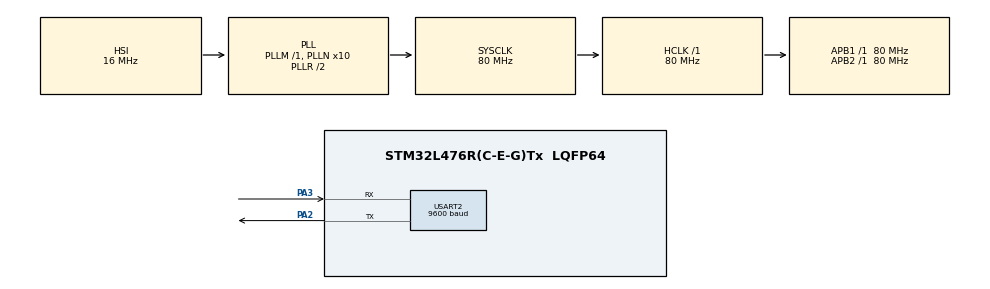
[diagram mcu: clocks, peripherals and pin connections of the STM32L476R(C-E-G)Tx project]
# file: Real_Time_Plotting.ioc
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Mcu.Family=STM32L4
Mcu.Name=STM32L476R(C-E-G)Tx
Mcu.Package=LQFP64
NVIC.PriorityGroup=NVIC_PRIORITYGROUP_4
NVIC.USART2_IRQn=true\:0\:0\:false\:false\:true\:true\:true\:true
PA2.Mode=Asynchronous
PA2.Signal=USART2_TX
PA3.Mode=Asynchronous
PA3.Signal=USART2_RX
ProjectManager.HeapSize=0x200
ProjectManager.StackSize=0x400
ProjectManager.TargetToolchain=STM32CubeIDE
RCC.ADCFreq_Value=64000000
RCC.AHBFreq_Value=80000000
RCC.APB1Freq_Value=80000000
RCC.APB1TimFreq_Value=80000000
RCC.APB2Freq_Value=80000000
RCC.APB2TimFreq_Value=80000000
RCC.CortexFreq_Value=80000000
RCC.HCLKFreq_Value=80000000
RCC.HSE_VALUE=8000000
RCC.HSI_VALUE=16000000
RCC.LSE_VALUE=32768
RCC.MSI_VALUE=4000000
RCC.PLLN=10
RCC.PLLSourceVirtual=RCC_PLLSOURCE_HSI
RCC.PREFETCH_ENABLE=1
RCC.SYSCLKFreq_VALUE=80000000
RCC.SYSCLKSource=RCC_SYSCLKSOURCE_PLLCLK
RCC.USBFreq_Value=64000000
RCC.VCOOutputFreq_Value=160000000
USART2.BaudRate=9600
USART2.VirtualMode-Asynchronous=VM_ASYNC
board=NUCLEO-L476RG

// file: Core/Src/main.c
/* USER CODE BEGIN Header */
/**
  ******************************************************************************
  * @file           : main.c
  * @brief          : Main program body
  ******************************************************************************
  * @attention
  *
  * Copyright (c) 2023 STMicroelectronics.
  * All rights reserved.
  *
  * This software is licensed under terms that can be found in the LICENSE file
  * in the root directory of this software component.
  * If no LICENSE file comes with this software, it is provided AS-IS.
  *
  ******************************************************************************
  */
/* USER CODE END Header */
#include "main.h"

/* USER CODE BEGIN Includes */
#include "stdlib.h"
#include "stdio.h"
#include "string.h"
#include "stdbool.h"

/* USER CODE END Includes */

UART_HandleTypeDef huart2;

/* USER CODE BEGIN PV */

char Tx_Buffer[50];
uint8_t Rx_Buffer[1];

/* USER CODE END PV */

void SystemClock_Config(void);
static void MX_GPIO_Init(void);
static void MX_USART2_UART_Init(void);

int main(void)
{

  /* MCU Configuration--------------------------------------------------------*/

  /* Reset of all peripherals, Initializes the Flash interface and the Systick. */
  HAL_Init();

  /* Configure the system clock */
  SystemClock_Config();

  /* Initialize all configured peripherals */
  MX_GPIO_Init();
  MX_USART2_UART_Init();

  /* USER CODE BEGIN 2 */

  bool data_stream_active = false;

  // Read data from the PC (Python code request).
  while (1) {
      HAL_UART_Receive(&huart2, (uint8_t *)Rx_Buffer, sizeof(Rx_Buffer), 100);
      // Check the request
      if (Rx_Buffer[0] == 103) { // if the user enters the 'g' character
          if (!data_stream_active) {
              //sprintf(Tx_Buffer, "Data stream initiated\n"); python script will handle logging infos to the user.
              HAL_UART_Transmit(&huart2, (uint8_t *)Tx_Buffer, strlen(Tx_Buffer), 100);
              data_stream_active = true;
          } else {
              //sprintf(Tx_Buffer, "Data stream already active\n");
              HAL_UART_Transmit(&huart2, (uint8_t *)Tx_Buffer, strlen(Tx_Buffer), 100);
          }
      } else if (Rx_Buffer[0] == 115) { // if the user enters the 's' character
          if (data_stream_active) {
              //sprintf(Tx_Buffer, "Data stream stopped\n");
              HAL_UART_Transmit(&huart2, (uint8_t *)Tx_Buffer, strlen(Tx_Buffer), 100);
              data_stream_active = false;
          } else {
              sprintf(Tx_Buffer, "Data stream not active\n");
              HAL_UART_Transmit(&huart2, (uint8_t *)Tx_Buffer, strlen(Tx_Buffer), 100);
          }
      } else if (Rx_Buffer[0] != '\0') { // if it's not 'g' or 's' and it's not empty.
          // Handle invalid request.
          sprintf(Tx_Buffer, "Invalid Request\n");
          HAL_UART_Transmit(&huart2, (uint8_t *)Tx_Buffer, strlen(Tx_Buffer), 100);
      }

      // If the data stream is active, proceed with data transmission
      while (data_stream_active) {//This while loop must be transformed as a task (Welcome to freeRtos). As well as the outer while loop.
          // Generate random values for x and y
          int x = rand() % 1000; // Generate a random value between 0 and 999 for x
          int y = rand() % 1000; // Generate a random value between 0 and 999 for y
          int z = rand() % 1000; // Generate a random value between 0 and 999 for y

          // Create a string with the format "x,y,z\n"
          sprintf(Tx_Buffer, "%d,%d,%d\n", x, y,z);

          // Transmit the string over UART
          HAL_UART_Transmit(&huart2, (uint8_t *)Tx_Buffer, strlen(Tx_Buffer), 100);

          // Introduce some delay before the next transmission (adjust the value based on your requirements)
          HAL_Delay(100);
      }
  }
}
void SystemClock_Config(void)
{
  RCC_OscInitTypeDef RCC_OscInitStruct = {0};
  RCC_ClkInitTypeDef RCC_ClkInitStruct = {0};

  /** Configure the main internal regulator output voltage
  */
  if (HAL_PWREx_ControlVoltageScaling(PWR_REGULATOR_VOLTAGE_SCALE1) != HAL_OK)
  {
    Error_Handler();
  }

  /** Initializes the RCC Oscillators according to the specified parameters
  * in the RCC_OscInitTypeDef structure.
  */
  RCC_OscInitStruct.OscillatorType = RCC_OSCILLATORTYPE_HSI;
  RCC_OscInitStruct.HSIState = RCC_HSI_ON;
  RCC_OscInitStruct.HSICalibrationValue = RCC_HSICALIBRATION_DEFAULT;
  RCC_OscInitStruct.PLL.PLLState = RCC_PLL_ON;
  RCC_OscInitStruct.PLL.PLLSource = RCC_PLLSOURCE_HSI;
  RCC_OscInitStruct.PLL.PLLM = 1;
  RCC_OscInitStruct.PLL.PLLN = 10;
  RCC_OscInitStruct.PLL.PLLP = RCC_PLLP_DIV7;
  RCC_OscInitStruct.PLL.PLLQ = RCC_PLLQ_DIV2;
  RCC_OscInitStruct.PLL.PLLR = RCC_PLLR_DIV2;
  if (HAL_RCC_OscConfig(&RCC_OscInitStruct) != HAL_OK)
  {
    Error_Handler();
  }

  /** Initializes the CPU, AHB and APB buses clocks
  */
  RCC_ClkInitStruct.ClockType = RCC_CLOCKTYPE_HCLK|RCC_CLOCKTYPE_SYSCLK
                              |RCC_CLOCKTYPE_PCLK1|RCC_CLOCKTYPE_PCLK2;
  RCC_ClkInitStruct.SYSCLKSource = RCC_SYSCLKSOURCE_PLLCLK;
  RCC_ClkInitStruct.AHBCLKDivider = RCC_SYSCLK_DIV1;
  RCC_ClkInitStruct.APB1CLKDivider = RCC_HCLK_DIV1;
  RCC_ClkInitStruct.APB2CLKDivider = RCC_HCLK_DIV1;

  if (HAL_RCC_ClockConfig(&RCC_ClkInitStruct, FLASH_LATENCY_4) != HAL_OK)
  {
    Error_Handler();
  }
}

static void MX_USART2_UART_Init(void)
{

  huart2.Instance = USART2;
  huart2.Init.BaudRate = 9600;
  huart2.Init.WordLength = UART_WORDLENGTH_8B;
  huart2.Init.StopBits = UART_STOPBITS_1;
  huart2.Init.Parity = UART_PARITY_NONE;
  huart2.Init.Mode = UART_MODE_TX_RX;
  huart2.Init.HwFlowCtl = UART_HWCONTROL_NONE;
  huart2.Init.OverSampling = UART_OVERSAMPLING_16;
  huart2.Init.OneBitSampling = UART_ONE_BIT_SAMPLE_DISABLE;
  huart2.AdvancedInit.AdvFeatureInit = UART_ADVFEATURE_NO_INIT;
  if (HAL_UART_Init(&huart2) != HAL_OK)
  {
    Error_Handler();
  }

}

static void MX_GPIO_Init(void)
{

  /* GPIO Ports Clock Enable */
  __HAL_RCC_GPIOA_CLK_ENABLE();

}

void Error_Handler(void)
{
  __disable_irq();
  while (1)
  {
  }
}
